# STM32G0B1xx register map
File version: 1.0
Registers are 32-bit, read-write, reset 0x0 unless marked. A register's access mark holds for its fields unless they carry their own. Offsets are from the block's base; [hi:lo] are bit positions; {n}, {i} and the like mark numbered series.

## FDCAN_CONFIG — FD Controller Area Network Configuration
Base 0x40006500
0x00 CKDIV — FDCAN clock divider register
  [3:0] PDIV — Input Clock Divider

## CRS — Clock Recovery System
Base 0x40006C00
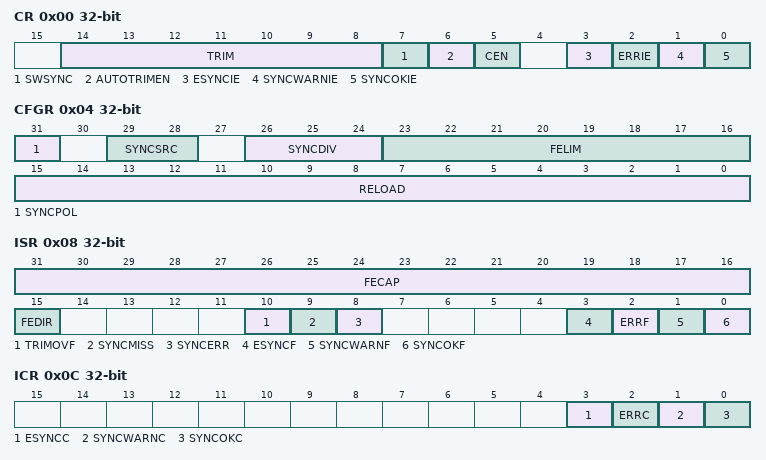
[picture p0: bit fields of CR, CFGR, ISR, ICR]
0x00 CR — CRS ccontrol register
  [14:8] TRIM — HSI48 oscillator smooth trimming
  [7] SWSYNC — Generate software SYNC event
  [6] AUTOTRIMEN — Automatic trimming enable
  [5] CEN — Frequency error counter enable
  [3] ESYNCIE — Expected SYNC interrupt enable
  [2] ERRIE — SYNC error or trimming error interrupt enable
  [1] SYNCWARNIE — SYNC warning interrupt enable
  [0] SYNCOKIE — SYNC event OK interrupt enable
0x04 CFGR — CRS configuration register
  [31] SYNCPOL — SYNC polarity selection
    0=RISING (Synchro Active on rising edge (default)); 1=FALLING (Synchro Active on falling edge)
  [29:28] SYNCSRC — SYNC signal source selection
    0=GPIO (Synchro Signal source GPIO); 1=LSE (Synchro Signal source LSE); 2=USB (Synchro Signal source USB SOF (default))
  [26:24] SYNCDIV — SYNC divider
    0=DIV_1 (Synchro Signal not divided (default)); 1=DIV_2 (Synchro Signal divided by 2); 2=DIV_4 (Synchro Signal divided by 4); 3=DIV_8 (Synchro Signal divided by 8); 4=DIV_16 (Synchro Signal divided by 16); 5=DIV_32 (Synchro Signal divided by 32); 6=DIV_64 (Synchro Signal divided by 64); 7=DIV_128 (Synchro Signal divided by 128)
  [23:16] FELIM — Frequency error limit
  [15:0] RELOAD — Counter reload value
0x08 ISR — CRS interrupt and status register
  [31:16] FECAP — Frequency error capture
  [15] FEDIR — Frequency error direction
    0=UP (Upcounting direction, the actual frequency is above the target); 1=DOWN (Downcounting direction, the actual frequency is below the target)
  [10] TRIMOVF — Trimming overflow or underflow
  [9] SYNCMISS — SYNC missed
  [8] SYNCERR — SYNC error
  [3] ESYNCF — Expected SYNC flag
  [2] ERRF — Error flag
  [1] SYNCWARNF — SYNC warning flag
  [0] SYNCOKF — SYNC event OK flag
0x0C ICR — CRS interrupt flag clear register
  [3] ESYNCC — Expected SYNC clear flag
  [2] ERRC — Error clear flag
  [1] SYNCWARNC — SYNC warning clear flag
  [0] SYNCOKC — SYNC event OK clear flag

## PWR — Power Control
Base 0x40007000
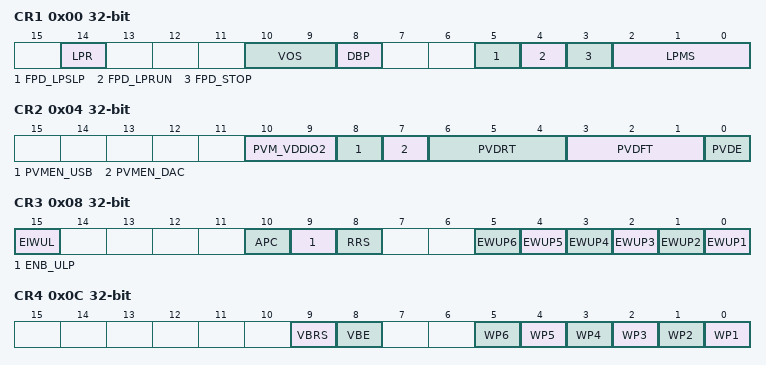
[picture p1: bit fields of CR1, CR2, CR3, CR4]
0x00 CR1 — PWR Power Control Register 1
  [14] LPR — Regulator Low-Power Run mode
  [10:9] VOS — Voltage scaling
    1=SCALE1; 2=SCALE2
  [8] DBP — Disable Backup Domain write protection
  [5] FPD_LPSLP — Flash power down mode during sleep
  [4] FPD_LPRUN — Flash power down mode during run
  [3] FPD_STOP — Flash power down mode during stop
  [2:0] LPMS — Low Power Mode Selection
    0=STOP0; 1=STOP1; 3=STANDBY; 4=SHUTDOWN
0x04 CR2 — PWR Power Control Register 2
  [10:9] PVM_VDDIO2 — VDDIO2 supply voltage monitoring
  [8] PVMEN_USB — USB Peripheral Voltage Monitor Enable
  [7] PVMEN_DAC — DAC supply voltage monitoring enable
  [6:4] PVDRT — PVD Rising Threshold Selection bit field
    {v}=PVDHLEVEL_{v} (v=0..7)
  [3:1] PVDFT — PVD Falling Threshold Selection bit field
    {v}=PVDLLEVEL_{v} (v=0..6)
  [0] PVDE — Programmable Voltage Detector Enable
0x08 CR3 — PWR Power Control Register 3
  [15] EIWUL — Enable Internal Wake-up line
  [10] APC — Apply pull-up and pull-down configuration
  [9] ENB_ULP — Enable sampling resistor bridge in the LPMU_RESET block
  [8] RRS — RAM retention in Standby mode
  [n-1] EWUP{n} (n=1..6) — Enable WKUP pin {n}
0x0C CR4 — PWR Power Control Register 4
  [9] VBRS — VBAT Battery charging Resistor Selection
    0=RESISTOR_5K; 1=RESISTOR_1_5K
  [8] VBE — VBAT Battery charging Enable
  [n-1] WP{n} (n=1..6) — Wake-Up Pin {n} polarity
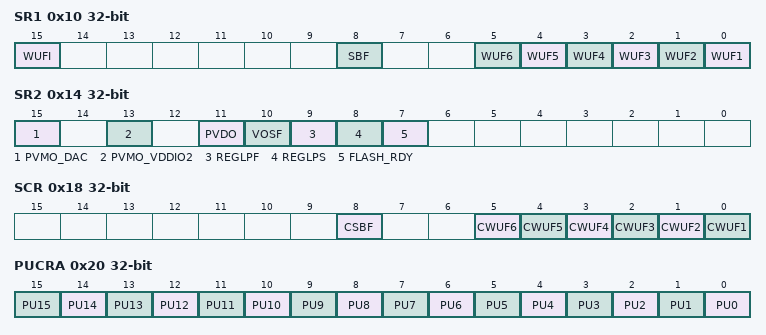
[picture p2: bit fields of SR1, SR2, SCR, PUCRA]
0x10 SR1 — PWR Power Status Register 1
  [15] WUFI — Wakeup Flag Internal
  [8] SBF — Standby Flag
  [n-1] WUF{n} (n=1..6) — Wakeup Flag {n}
0x14 SR2 — PWR Power Status Register 2
  [15] PVMO_DAC — VDDA monitoring output flag
  [13] PVMO_VDDIO2 — Power Voltage Monitoring Output
  [11] PVDO — Power voltage detector output
  [10] VOSF — Voltage Scaling Flag
  [9] REGLPF — Regulator Low Power flag
  [8] REGLPS — Regulator Low Power started
  [7] FLASH_RDY — Flash Ready
0x18 SCR — PWR Power Status Clear Register
  [8] CSBF — Clear Standby Flag
  [n-1] CWUF{n} (n=1..6) — Clear Wake-up Flag {n}
0x20 PUCRA — PWR Pull-Up Control Register of port A
  [n] PU{n} (n=0..15) — Pin PA{n} Pull-Up set
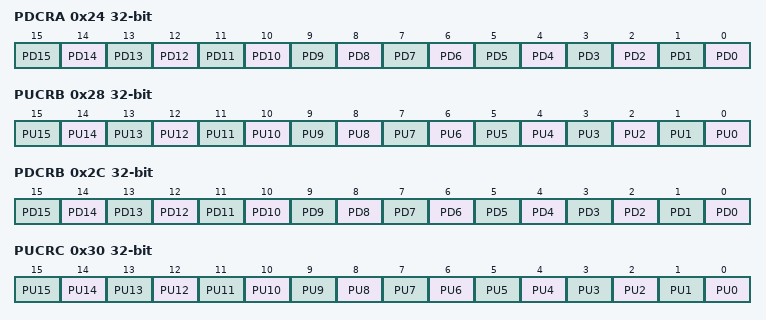
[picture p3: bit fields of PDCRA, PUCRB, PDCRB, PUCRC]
0x24 PDCRA — PWR Pull-Down Control Register of port A
  [n] PD{n} (n=0..15) — Pin PA{n} Pull-Down set
0x28 PUCRB — PWR Pull-Up Control Register of port B
  [n] PU{n} (n=0..15) — Pin PB{n} Pull-Up set
0x2C PDCRB — PWR Pull-Down Control Register of port B
  [n] PD{n} (n=0..15) — Pin PB{n} Pull-Down set
0x30 PUCRC — PWR Pull-Up Control Register of port C
  [n] PU{n} (n=0..15) — Pin PC{n} Pull-Up set
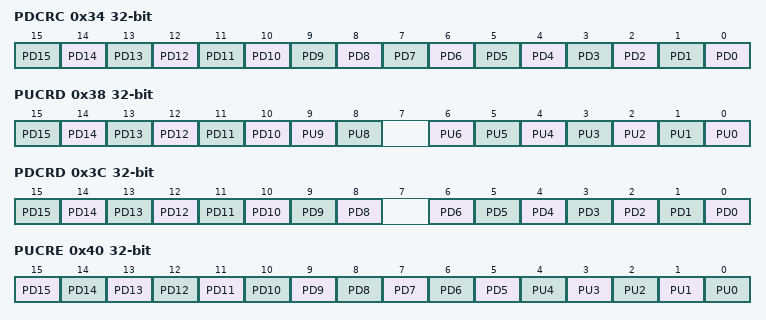
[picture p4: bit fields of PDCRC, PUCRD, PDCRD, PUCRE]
0x34 PDCRC — PWR Pull-Down Control Register of port C
  [n] PD{n} (n=0..15) — Pin PC{n} Pull-Down set
0x38 PUCRD — PWR Pull-Up Control Register of port D
  [n] PD{n} (n=10..15) — Pin PD{n} Pull-Up set
  [9] PU9 — Pin PD9 Pull-Up set
  [8] PU8 — Pin PD8 Pull-Up set
  [n] PU{n} (n=0..6) — Pin PD{n} Pull-Up set
0x3C PDCRD — PWR Pull-Down Control Register of port D
  [n] PD{n} (n=8..15) — Pin PD{n} Pull-Down set
  [n] PD{n} (n=0..6) — Pin PD{n} Pull-Down set
0x40 PUCRE — PWR Pull-Up Control Register of port E
  [n] PD{n} (n=5..15) — Pin PE{n} Pull-Up set
  [n] PU{n} (n=0..4) — Pin PE{n} Pull-Up set
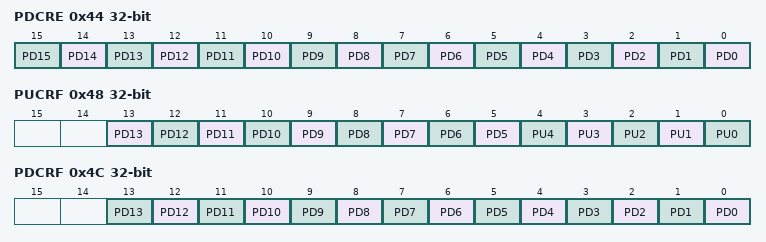
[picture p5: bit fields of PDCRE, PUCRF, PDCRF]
0x44 PDCRE — PWR Pull-Down Control Register of port E
  [n] PD{n} (n=0..15) — Pin PE{n} Pull-Down set
0x48 PUCRF — PWR Pull-Up Control Register of port F
  [n] PD{n} (n=5..13) — Pin PF{n} Pull-Up set
  [n] PU{n} (n=0..4) — Pin PF{n} Pull-Up set
0x4C PDCRF — PWR Pull-Down Control Register of port F
  [n] PD{n} (n=0..13) — Pin PF{n} Pull-Down set
